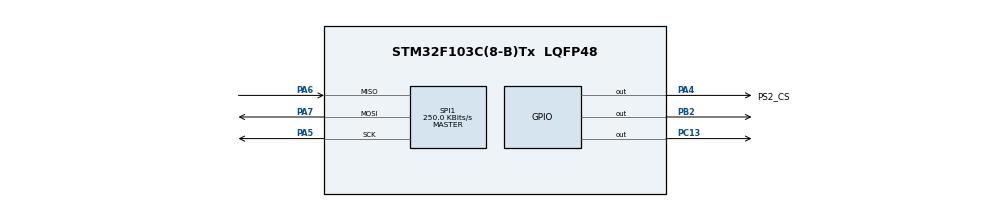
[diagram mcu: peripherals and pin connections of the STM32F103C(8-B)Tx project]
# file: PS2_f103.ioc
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Mcu.Family=STM32F1
Mcu.Name=STM32F103C(8-B)Tx
Mcu.Package=LQFP48
NVIC.PriorityGroup=NVIC_PRIORITYGROUP_4
PA13.Mode=Serial_Wire
PA13.Signal=SYS_JTMS-SWDIO
PA14.Mode=Serial_Wire
PA14.Signal=SYS_JTCK-SWCLK
PA4.GPIO_Label=PS2_CS
PA4.Signal=GPIO_Output
PA5.Mode=Full_Duplex_Master
PA5.Signal=SPI1_SCK
PA6.Mode=Full_Duplex_Master
PA6.Signal=SPI1_MISO
PA7.Mode=Full_Duplex_Master
PA7.Signal=SPI1_MOSI
PB2.Signal=GPIO_Output
PC13-TAMPER-RTC.Signal=GPIO_Output
ProjectManager.HeapSize=0x200
ProjectManager.StackSize=0x400
ProjectManager.TargetToolchain=STM32CubeIDE
RCC.APB1Freq_Value=8000000
RCC.APB2Freq_Value=8000000
SPI1.BaudRatePrescaler=SPI_BAUDRATEPRESCALER_32
SPI1.CLKPhase=SPI_PHASE_2EDGE
SPI1.CLKPolarity=SPI_POLARITY_HIGH
SPI1.CalculateBaudRate=250.0 KBits/s
SPI1.Direction=SPI_DIRECTION_2LINES
SPI1.FirstBit=SPI_FIRSTBIT_LSB
SPI1.Mode=SPI_MODE_MASTER
SPI1.VirtualType=VM_MASTER
board=custom

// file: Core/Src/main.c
/* USER CODE BEGIN Header */
/**
  ******************************************************************************
  * @file           : main.c
  * @brief          : Main program body
  ******************************************************************************
  * @attention
  *
  * Copyright (c) 2025 STMicroelectronics.
  * All rights reserved.
  *
  * This software is licensed under terms that can be found in the LICENSE file
  * in the root directory of this software component.
  * If no LICENSE file comes with this software, it is provided AS-IS.
  *
  ******************************************************************************
  */
/* USER CODE END Header */
#include "main.h"
#include "spi.h"
#include "gpio.h"

/* USER CODE BEGIN Includes */
#include <stdio.h>
#include "ps2.h"

/* USER CODE END Includes */

/* USER CODE BEGIN PV */
 ps2_handle_t ps2 = {
		 .spi_handle = &hspi1
 };
/* USER CODE END PV */

void SystemClock_Config(void);

int main(void)
{

  /* MCU Configuration--------------------------------------------------------*/

  /* Reset of all peripherals, Initializes the Flash interface and the Systick. */
  HAL_Init();

  /* Configure the system clock */
  SystemClock_Config();

  /* Initialize all configured peripherals */
  MX_GPIO_Init();
  MX_SPI1_Init();
  /* USER CODE BEGIN 2 */

 uint8_t success = true;
  /* USER CODE END 2 */

  /* Infinite loop */
  while (1)
  {

    /* USER CODE BEGIN 3 */
	  success = PS2_ReadData(&ps2);
	  if (success) HAL_GPIO_WritePin(GPIOB, GPIO_PIN_2, GPIO_PIN_SET);
	  else HAL_GPIO_WritePin(GPIOB, GPIO_PIN_2, GPIO_PIN_RESET);
	  HAL_Delay(20);
  }
  /* USER CODE END 3 */
}

void SystemClock_Config(void)
{
  RCC_OscInitTypeDef RCC_OscInitStruct = {0};
  RCC_ClkInitTypeDef RCC_ClkInitStruct = {0};

  /** Initializes the RCC Oscillators according to the specified parameters
  * in the RCC_OscInitTypeDef structure.
  */
  RCC_OscInitStruct.OscillatorType = RCC_OSCILLATORTYPE_HSI;
  RCC_OscInitStruct.HSIState = RCC_HSI_ON;
  RCC_OscInitStruct.HSICalibrationValue = RCC_HSICALIBRATION_DEFAULT;
  RCC_OscInitStruct.PLL.PLLState = RCC_PLL_NONE;
  if (HAL_RCC_OscConfig(&RCC_OscInitStruct) != HAL_OK)
  {
    Error_Handler();
  }

  /** Initializes the CPU, AHB and APB buses clocks
  */
  RCC_ClkInitStruct.ClockType = RCC_CLOCKTYPE_HCLK|RCC_CLOCKTYPE_SYSCLK
                              |RCC_CLOCKTYPE_PCLK1|RCC_CLOCKTYPE_PCLK2;
  RCC_ClkInitStruct.SYSCLKSource = RCC_SYSCLKSOURCE_HSI;
  RCC_ClkInitStruct.AHBCLKDivider = RCC_SYSCLK_DIV1;
  RCC_ClkInitStruct.APB1CLKDivider = RCC_HCLK_DIV1;
  RCC_ClkInitStruct.APB2CLKDivider = RCC_HCLK_DIV1;

  if (HAL_RCC_ClockConfig(&RCC_ClkInitStruct, FLASH_LATENCY_0) != HAL_OK)
  {
    Error_Handler();
  }
}

void Error_Handler(void)
{
  __disable_irq();
  while (1)
  {
  }
}
